# RL6955_IP_SVD register map
Vendor: Realtek
Registers are 32-bit, read-write, reset 0x0 unless marked. A register's access mark holds for its fields unless they carry their own. Offsets are from the block's base; [hi:lo] are bit positions; {n}, {i} and the like mark numbered series.

## MGEN_OFF
Base 0x40000000
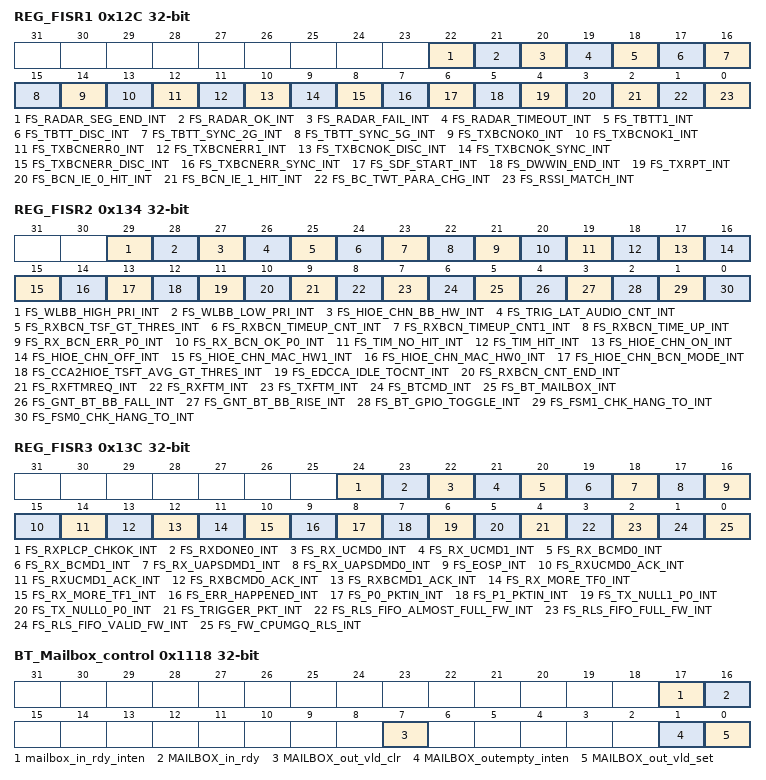
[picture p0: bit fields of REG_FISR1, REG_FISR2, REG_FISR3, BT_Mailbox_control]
0x12C REG_FISR1 ro
  [22] FS_RADAR_SEG_END_INT, [21] FS_RADAR_OK_INT, [20] FS_RADAR_FAIL_INT, [19] FS_RADAR_TIMEOUT_INT, [18] FS_TBTT1_INT, [17] FS_TBTT_DISC_INT, [16] FS_TBTT_SYNC_2G_INT, [15] FS_TBTT_SYNC_5G_INT, [14] FS_TXBCNOK0_INT, [13] FS_TXBCNOK1_INT, [12] FS_TXBCNERR0_INT, [11] FS_TXBCNERR1_INT, [10] FS_TXBCNOK_DISC_INT, [9] FS_TXBCNOK_SYNC_INT, [8] FS_TXBCNERR_DISC_INT, [7] FS_TXBCNERR_SYNC_INT, [6] FS_SDF_START_INT, [5] FS_DWWIN_END_INT, [4] FS_TXRPT_INT, [3] FS_BCN_IE_0_HIT_INT, [2] FS_BCN_IE_1_HIT_INT, [1] FS_BC_TWT_PARA_CHG_INT, [0] FS_RSSI_MATCH_INT
0x134 REG_FISR2 ro
  [29] FS_WLBB_HIGH_PRI_INT
  [28] FS_WLBB_LOW_PRI_INT
  [27] FS_HIOE_CHN_BB_HW_INT
  [26] FS_TRIG_LAT_AUDIO_CNT_INT
  [25] FS_RXBCN_TSF_GT_THRES_INT
  [24] FS_RXBCN_TIMEUP_CNT_INT
  [23] FS_RXBCN_TIMEUP_CNT1_INT
  [22] FS_RXBCN_TIME_UP_INT
  [21] FS_RX_BCN_ERR_P0_INT
  [20] FS_RX_BCN_OK_P0_INT
  [19] FS_TIM_NO_HIT_INT
  [18] FS_TIM_HIT_INT
  [17] FS_HIOE_CHN_ON_INT
  [16] FS_HIOE_CHN_OFF_INT
  [15] FS_HIOE_CHN_MAC_HW1_INT
  [14] FS_HIOE_CHN_MAC_HW0_INT
  [13] FS_HIOE_CHN_BCN_MODE_INT
  [12] FS_CCA2HIOE_TSFT_AVG_GT_THRES_INT
  [11] FS_EDCCA_IDLE_TOCNT_INT
  [10] FS_RXBCN_CNT_END_INT
  [9] FS_RXFTMREQ_INT — If RXFTMREQ_INT_EN =1. When HW receive FTMREQ packet, it will generate interrupt to firmware.
  [8] FS_RXFTM_INT — If RXFTM_INT_EN =1. When HW receive FTM and transmit ACK frame successfully, the BB generate FTM report. It will generate interrupt to firmware.
  [7] FS_TXFTM_INT — If TXFTM_INT_EN =1. When HW transmit FTM and receive ACK frame successfully, the BB generate FTM report. It will generate interrupt to firmware.
  [6] FS_BTCMD_INT
  [5] FS_BT_MAILBOX_INT
  [4] FS_GNT_BT_BB_FALL_INT
  [3] FS_GNT_BT_BB_RISE_INT
  [2] FS_BT_GPIO_TOGGLE_INT
  [1] FS_FSM1_CHK_HANG_TO_INT
  [0] FS_FSM0_CHK_HANG_TO_INT
0x13C REG_FISR3 ro
  [24] FS_RXPLCP_CHKOK_INT — RXPCLP check ok interrupt
  [23] FS_RXDONE0_INT — Rx Packet 0 done interrupt (for WOL release packet)
  [22] FS_RX_UCMD0_INT — The interrupt is issued while receiving unicast data frame with More Data=0
  [21] FS_RX_UCMD1_INT — The interrupt is issued while receiving unicast data frame with More Data=1
  [20] FS_RX_BCMD0_INT — The interrupt is issued while receiving broadcast data frame with More Data=0
  [19] FS_RX_BCMD1_INT — The interrupt is issued while receiving broadcast data frame with More Data=1
  [18] FS_RX_UAPSDMD1_INT — Setting this bit indicates Rx pkt is matched with one of below: 1.) QoS Unicast data frame with MD=1, UAPSD=0 2.) NonQoS Unicast data frame with MD=1
  [17] FS_RX_UAPSDMD0_INT — Setting this bit indicates Rx pkt is matched with one of below: 1.) QoS Unicast data frame with MD=0, UAPSD=0 2.) NonQoS Unicast data frame with MD=0
  [16] FS_EOSP_INT — EOSP_INT interrupt mask
  [15] FS_RXUCMD0_ACK_INT
  [14] FS_RXUCMD1_ACK_INT
  [13] FS_RXBCMD0_ACK_INT
  [12] FS_RXBCMD1_ACK_INT
  [11] FS_RX_MORE_TF0_INT
  [10] FS_RX_MORE_TF1_INT
  [9] FS_ERR_HAPPENED_INT — FWHW/ WMAC error status interrupt(0x4E2[15:0], 0x6B8[31:0]). WMAC error state will be recovered by HW, the others won't.
  [8] FS_P0_PKTIN_INT — port 0 packet assign to queue interrupt
  [7] FS_P1_PKTIN_INT — port 1 packet assign to queue interrupt
  [6] FS_TX_NULL1_P0_INT — TX null 1 packet done interrupt
  [5] FS_TX_NULL0_P0_INT — TX null 0 packet done interrupt
  [4] FS_TRIGGER_PKT_INT — tx TRIGGER_PKT interrupt
  [3] FS_RLS_FIFO_ALMOST_FULL_FW_INT
  [2] FS_RLS_FIFO_FULL_FW_INT
  [1] FS_RLS_FIFO_VALID_FW_INT
  [0] FS_FW_CPUMGQ_RLS_INT
{0x1B4+4i} REG_FW_DBG_{i} (i=1..4)
  [31:0] FW_DBG_{i}
{0x10EC+4i} REG_FW_DBG_{i} (i=5..8)
  [31:0] FW_DBG_{i}
0x1110 BT_MAILBOX_DATA_IN_L ro
  [31:0] MAILBOX_DATA_IN_BT2WL_L
0x1114 BT_MAILBOX_DATA_IN_H ro
  [31:0] MAILBOX_DATA_IN_BT2WL_H
0x1118 BT_Mailbox_control access per field
  [17] mailbox_in_rdy_inten rw — Mailbox IN ready interrupt enable
  [16] MAILBOX_in_rdy ro — Mailbox ready BT2Wifi
  [7] MAILBOX_out_vld_clr wo — clear Mailbox ACK Wifi2BT
  [1] MAILBOX_outempty_inten rw — Mailbox OUT empty interrupt enable
  [0] MAILBOX_out_vld_set ro — Mailbox ACK Wifi2BT
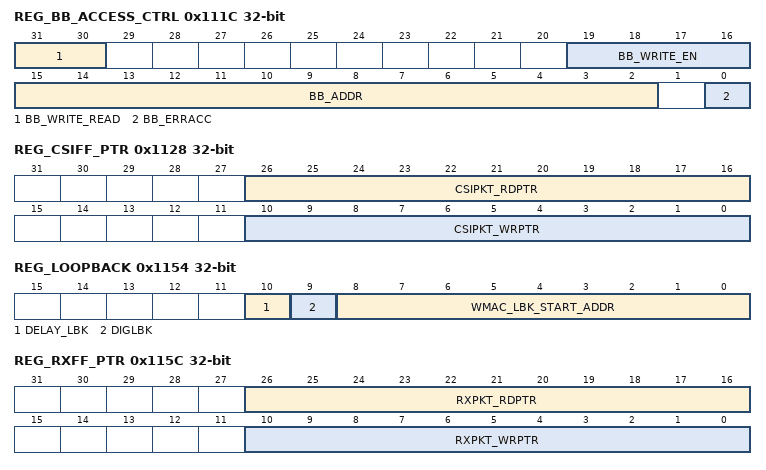
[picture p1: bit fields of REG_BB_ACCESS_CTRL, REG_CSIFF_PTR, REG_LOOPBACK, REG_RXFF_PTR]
0x111C REG_BB_ACCESS_CTRL access per field
  [31:30] BB_WRITE_READ ro — 00 : No Active Baseband cycle 01 : Baseband Write Access (auto return to 00 when access finished) 1X : Baseband Read Access (auto return to 00 when access finished)
  [19:16] BB_WRITE_EN ro — Byte Write Enable
  [15:2] BB_ADDR ro — Baseband Access Write/Read Address (in DW unit)
  [0] BB_ERRACC ro — Duplicate Access when previous cycle pending (write one clear)
0x1120 REG_BB_ACCESS_DATA ro
  [31:0] BB_DATA — Baseband Access Write/Read Data (in DW unit)
0x1128 REG_CSIFF_PTR ro — CSI FIFO Read/write pointer
  [26:16] CSIPKT_RDPTR — The read pointer address of CSIBUFFER. The value is set to the physical LX bus address. 8byte unit
  [10:0] CSIPKT_WRPTR — The write pointer address of CSIBUFFER. The value is set to the physical LX bus address. 8byte unit
0x112C REG_TXBD_FIFO_CFG0
  [31:0] SW_WR_TXBD_DATA — SW write host address to TXBD FIFO
0x1130 REG_TXRLS_FIFO_CFG0 ro
  [31:0] DRV_RD_TXRLS_DATA — Driver read released host address from memory
0x1134 REG_TXRLS_FIFO_CFG1 ro
  [31:0] FW_RD_TXRLS_DATA — FW read released host address from memory
0x1138 REG_TXRPT_BUF_CFG0 ro
  [31:0] SW_RD_TXRPT_DATA — FW read TXRPT data from memory
0x113C REG_RXBD_FIFO_CFG0
  [31:0] SW_WR_RXBD_DATA — SW write host address to RXBD FIFO
0x1140 REG_CSIBD_FIFO_CFG0
  [31:0] SW_WR_CSIBD_DATA — SW write host address to CSIBD FIFO
0x1144 REG_CSIBD_RDATA ro
  [31:0] SW_RD_CSIBD_DATA — SW read released CSIBD host address from memory
0x1148 REG_RXBD_RDATA ro
  [31:0] SW_RD_RXBD_DATA — SW read released RXBD host address from memory
0x1154 REG_LOOPBACK
  [10] DELAY_LBK — delay loop back mode
  [9] DIGLBK — loop back mode
  [8:0] WMAC_LBK_START_ADDR — start address of delay loopback pkt in ext_rxpktbuf
0x1158 REG_DUMMY_PAGE1_OFF
  [7:0] DUMMY
0x115C REG_RXFF_PTR ro — RX FIFO Read/write pointer
  [26:16] RXPKT_RDPTR — The read pointer address of RXFF0. The value is set to the physical LX bus address. 8byte unit
  [10:0] RXPKT_WRPTR — The write pointer address of RXFF0. The value is set to the physical LX bus address. 8byte unit
0x1160 BT_MAILBOX_DATA_OUT_L
  [31:0] MAILBOX_DATA_OUT_WL2BT_L
0x1164 BT_MAILBOX_DATA_OUT_H
  [31:0] MAILBOX_DATA_OUT_WL2BT_H
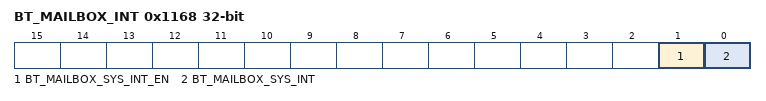
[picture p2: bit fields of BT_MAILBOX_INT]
0x1168 BT_MAILBOX_INT access per field
  [1] BT_MAILBOX_SYS_INT_EN rw — bt2wl and wl2bt mailbox interrupt mask
  [0] BT_MAILBOX_SYS_INT ro — bt2wl and wl2bt mailbox interrupt, to system intr
